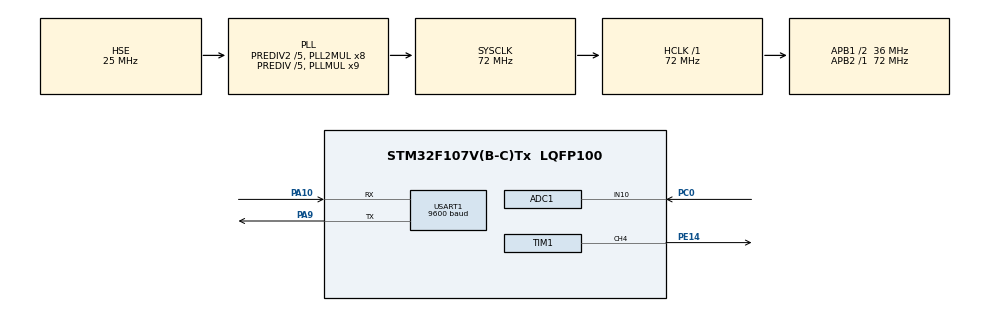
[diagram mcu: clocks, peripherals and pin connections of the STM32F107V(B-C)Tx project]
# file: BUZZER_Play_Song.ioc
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ADC1.Channel-0\#ChannelRegularConversion=ADC_CHANNEL_10
ADC1.NbrOfConversionFlag=1
ADC1.Rank-0\#ChannelRegularConversion=1
ADC1.SamplingTime-0\#ChannelRegularConversion=ADC_SAMPLETIME_1CYCLE_5
ADC1.master=1
Mcu.Family=STM32F1
Mcu.Name=STM32F107V(B-C)Tx
Mcu.Package=LQFP100
NVIC.PriorityGroup=NVIC_PRIORITYGROUP_4
OSC_IN.Mode=HSE-External-Oscillator
OSC_IN.Signal=RCC_OSC_IN
OSC_OUT.Mode=HSE-External-Oscillator
OSC_OUT.Signal=RCC_OSC_OUT
PA10.Mode=Asynchronous
PA10.Signal=USART1_RX
PA13.Mode=Serial_Wire
PA13.Signal=SYS_JTMS-SWDIO
PA14.Mode=Serial_Wire
PA14.Signal=SYS_JTCK-SWCLK
PA9.Mode=Asynchronous
PA9.Signal=USART1_TX
PC0.Signal=ADCx_IN10
PE14.Signal=S_TIM1_CH4
ProjectManager.HeapSize=0x200
ProjectManager.StackSize=0x400
ProjectManager.TargetToolchain=MDK-ARM V5
RCC.ADCPresc=RCC_ADCPCLK2_DIV8
RCC.AHBFreq_Value=72000000
RCC.APB1CLKDivider=RCC_HCLK_DIV2
RCC.APB1Freq_Value=36000000
RCC.APB1TimFreq_Value=72000000
RCC.APB2Freq_Value=72000000
RCC.APB2TimFreq_Value=72000000
RCC.HCLKFreq_Value=72000000
RCC.HSEDivPLL=RCC_HSE_PREDIV_DIV5
RCC.HSE_VALUE=25000000
RCC.PLLMUL=RCC_PLL_MUL9
RCC.PLLSourceVirtual=RCC_PLLSOURCE_HSE
RCC.Prediv1Source=RCC_PREDIV1_SOURCE_PLL2
RCC.Prediv2=RCC_HSE_PREDIV2_DIV5
RCC.SYSCLKFreq_VALUE=72000000
RCC.SYSCLKSource=RCC_SYSCLKSOURCE_PLLCLK
RCC.USBFreq_Value=48000000
SH.ADCx_IN10.0=ADC1_IN10,IN10
SH.S_TIM1_CH4.0=TIM1_CH4,PWM Generation4 CH4
TIM1.Channel-PWM\ Generation4\ CH4=TIM_CHANNEL_4
TIM1.Period=0xFFFF
TIM1.Prescaler=21
TIM1.Pulse-PWM\ Generation4\ CH4=50
USART1.BaudRate=9600
USART1.VirtualMode=VM_ASYNC
board=custom

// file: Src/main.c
/* USER CODE BEGIN Header */
/**
  ******************************************************************************
  * @file           : main.c
  * @brief          : Main program body
  ******************************************************************************
  ** This notice applies to any and all portions of this file
  * that are not between comment pairs USER CODE BEGIN and
  * USER CODE END. Other portions of this file, whether
  * inserted by the user or by software development tools
  * are owned by their respective copyright owners.
  *
  * COPYRIGHT(c) 2019 STMicroelectronics
  *
  * Redistribution and use in source and binary forms, with or without modification,
  * are permitted provided that the following conditions are met:
  *   1. Redistributions of source code must retain the above copyright notice,
  *      this list of conditions and the following disclaimer.
  *   2. Redistributions in binary form must reproduce the above copyright notice,
  *      this list of conditions and the following disclaimer in the documentation
  *      and/or other materials provided with the distribution.
  *   3. Neither the name of STMicroelectronics nor the names of its contributors
  *      may be used to endorse or promote products derived from this software
  *      without specific prior written permission.
  *
  * THIS SOFTWARE IS PROVIDED BY THE COPYRIGHT HOLDERS AND CONTRIBUTORS "AS IS"
  * AND ANY EXPRESS OR IMPLIED WARRANTIES, INCLUDING, BUT NOT LIMITED TO, THE
  * IMPLIED WARRANTIES OF MERCHANTABILITY AND FITNESS FOR A PARTICULAR PURPOSE ARE
  * DISCLAIMED. IN NO EVENT SHALL THE COPYRIGHT HOLDER OR CONTRIBUTORS BE LIABLE
  * FOR ANY DIRECT, INDIRECT, INCIDENTAL, SPECIAL, EXEMPLARY, OR CONSEQUENTIAL
  * DAMAGES (INCLUDING, BUT NOT LIMITED TO, PROCUREMENT OF SUBSTITUTE GOODS OR
  * SERVICES; LOSS OF USE, DATA, OR PROFITS; OR BUSINESS INTERRUPTION) HOWEVER
  * CAUSED AND ON ANY THEORY OF LIABILITY, WHETHER IN CONTRACT, STRICT LIABILITY,
  * OR TORT (INCLUDING NEGLIGENCE OR OTHERWISE) ARISING IN ANY WAY OUT OF THE USE
  * OF THIS SOFTWARE, EVEN IF ADVISED OF THE POSSIBILITY OF SUCH DAMAGE.
  *
  ******************************************************************************
  */
/* USER CODE END Header */

#include "main.h"

/* USER CODE BEGIN Includes */
#include <math.h>
/* USER CODE END Includes */

ADC_HandleTypeDef hadc1;

TIM_HandleTypeDef htim1;

UART_HandleTypeDef huart1;

/* USER CODE BEGIN PV */
int8_t song[] = {-3, 2, 5, 4, 2, 5, 2, 4, 2, -2, 0, -3};
uint8_t songSize = 12;
/* USER CODE END PV */

void SystemClock_Config(void);
static void MX_GPIO_Init(void);
static void MX_TIM1_Init(void);
static void MX_ADC1_Init(void);
static void MX_USART1_UART_Init(void);

	uint8_t data[1] = {'0'};

int main(void)
{

  /* MCU Configuration--------------------------------------------------------*/

  /* Reset of all peripherals, Initializes the Flash interface and the Systick. */
  HAL_Init();

  /* Configure the system clock */
  SystemClock_Config();

  /* Initialize all configured peripherals */
  MX_GPIO_Init();
  MX_TIM1_Init();
  MX_ADC1_Init();
  MX_USART1_UART_Init();
  /* USER CODE BEGIN 2 */
	HAL_TIM_PWM_Start(&htim1,TIM_CHANNEL_4);
	HAL_ADCEx_Calibration_Start(&hadc1);
  /* USER CODE END 2 */

  /* Infinite loop */
  /* USER CODE BEGIN WHILE */
	uint32_t adcReturnValue = 0;
	int8_t n = 0;
	double_t noteFreq = 440;
	uint16_t arr = 1000;
	uint16_t songIndex = 0;

  while (1)
  {

		/*

		LAB PART 1 - 1
			if (songIndex<songSize){
				n = song[songIndex++] - 6;
				noteFreq = 440*pow(1.059463094359, n);
				arr = (double_t)72000000 / noteFreq / (htim1.Init.Prescaler+ 1) - 1;
				__HAL_TIM_SET_AUTORELOAD(&htim1, arr);//set the new period
				__HAL_TIM_SET_COMPARE(&htim1, TIM_CHANNEL_4, (int)arr/2);//keep 50% duty cycle
				__NOP();
			}
			HAL_Delay(500);
		*/

		/*
			LAB PART 1 - 2

		HAL_ADC_Start(&hadc1);

		if ( HAL_ADC_PollForConversion(&hadc1,1000) == HAL_OK){
			adcReturnValue = HAL_ADC_GetValue(&hadc1);
			n = floor(adcReturnValue / 42.217) - 36;
			noteFreq = 440*pow(1.059463094359, n);
			arr = (double_t)72000000 / noteFreq / (htim1.Init.Prescaler+ 1) - 1;
			__HAL_TIM_SET_AUTORELOAD(&htim1, arr);//set the new period
			__HAL_TIM_SET_COMPARE(&htim1, TIM_CHANNEL_4, (int)arr/2);//keep 50% duty cycle
		}
		HAL_Delay(100);
		HAL_ADC_Stop(&hadc1);*/

			/*
						LAB PART 2

				HAL_UART_Receive(&huart1, data, sizeof(data), HAL_MAX_DELAY);

				n = (int8_t)data[0] - 63;
				noteFreq = 440*pow(1.059463094359, n);
				arr = (double_t)72000000 / noteFreq / (htim1.Init.Prescaler+ 1) - 1;
				__HAL_TIM_SET_AUTORELOAD(&htim1, arr);//set the new period
				__HAL_TIM_SET_COMPARE(&htim1, TIM_CHANNEL_4, (int)arr/2);//keep 50% duty cycle
				__NOP();

			HAL_Delay(500);
			 HAL_UART_Transmit(&huart1, data, sizeof(data), HAL_MAX_DELAY);

			*/
    /* USER CODE END WHILE */

  }
}

void SystemClock_Config(void)
{
  RCC_OscInitTypeDef RCC_OscInitStruct = {0};
  RCC_ClkInitTypeDef RCC_ClkInitStruct = {0};
  RCC_PeriphCLKInitTypeDef PeriphClkInit = {0};

  /**Initializes the CPU, AHB and APB busses clocks
  */
  RCC_OscInitStruct.OscillatorType = RCC_OSCILLATORTYPE_HSE;
  RCC_OscInitStruct.HSEState = RCC_HSE_ON;
  RCC_OscInitStruct.HSEPredivValue = RCC_HSE_PREDIV_DIV5;
  RCC_OscInitStruct.HSIState = RCC_HSI_ON;
  RCC_OscInitStruct.Prediv1Source = RCC_PREDIV1_SOURCE_PLL2;
  RCC_OscInitStruct.PLL.PLLState = RCC_PLL_ON;
  RCC_OscInitStruct.PLL.PLLSource = RCC_PLLSOURCE_HSE;
  RCC_OscInitStruct.PLL.PLLMUL = RCC_PLL_MUL9;
  RCC_OscInitStruct.PLL2.PLL2State = RCC_PLL2_ON;
  RCC_OscInitStruct.PLL2.PLL2MUL = RCC_PLL2_MUL8;
  RCC_OscInitStruct.PLL2.HSEPrediv2Value = RCC_HSE_PREDIV2_DIV5;
  if (HAL_RCC_OscConfig(&RCC_OscInitStruct) != HAL_OK)
  {
    Error_Handler();
  }
  /**Initializes the CPU, AHB and APB busses clocks
  */
  RCC_ClkInitStruct.ClockType = RCC_CLOCKTYPE_HCLK|RCC_CLOCKTYPE_SYSCLK
                              |RCC_CLOCKTYPE_PCLK1|RCC_CLOCKTYPE_PCLK2;
  RCC_ClkInitStruct.SYSCLKSource = RCC_SYSCLKSOURCE_PLLCLK;
  RCC_ClkInitStruct.AHBCLKDivider = RCC_SYSCLK_DIV1;
  RCC_ClkInitStruct.APB1CLKDivider = RCC_HCLK_DIV2;
  RCC_ClkInitStruct.APB2CLKDivider = RCC_HCLK_DIV1;

  if (HAL_RCC_ClockConfig(&RCC_ClkInitStruct, FLASH_LATENCY_2) != HAL_OK)
  {
    Error_Handler();
  }
  PeriphClkInit.PeriphClockSelection = RCC_PERIPHCLK_ADC;
  PeriphClkInit.AdcClockSelection = RCC_ADCPCLK2_DIV8;
  if (HAL_RCCEx_PeriphCLKConfig(&PeriphClkInit) != HAL_OK)
  {
    Error_Handler();
  }
  /**Configure the Systick interrupt time
  */
  __HAL_RCC_PLLI2S_ENABLE();
}

static void MX_ADC1_Init(void)
{

  ADC_ChannelConfTypeDef sConfig = {0};

  /**Common config
  */
  hadc1.Instance = ADC1;
  hadc1.Init.ScanConvMode = ADC_SCAN_DISABLE;
  hadc1.Init.ContinuousConvMode = DISABLE;
  hadc1.Init.DiscontinuousConvMode = DISABLE;
  hadc1.Init.ExternalTrigConv = ADC_SOFTWARE_START;
  hadc1.Init.DataAlign = ADC_DATAALIGN_RIGHT;
  hadc1.Init.NbrOfConversion = 1;
  if (HAL_ADC_Init(&hadc1) != HAL_OK)
  {
    Error_Handler();
  }
  /**Configure Regular Channel
  */
  sConfig.Channel = ADC_CHANNEL_10;
  sConfig.Rank = ADC_REGULAR_RANK_1;
  sConfig.SamplingTime = ADC_SAMPLETIME_1CYCLE_5;
  if (HAL_ADC_ConfigChannel(&hadc1, &sConfig) != HAL_OK)
  {
    Error_Handler();
  }

}

static void MX_TIM1_Init(void)
{

  TIM_MasterConfigTypeDef sMasterConfig = {0};
  TIM_OC_InitTypeDef sConfigOC = {0};
  TIM_BreakDeadTimeConfigTypeDef sBreakDeadTimeConfig = {0};

  htim1.Instance = TIM1;
  htim1.Init.Prescaler = 21;
  htim1.Init.CounterMode = TIM_COUNTERMODE_UP;
  htim1.Init.Period = 0xFFFF;
  htim1.Init.ClockDivision = TIM_CLOCKDIVISION_DIV1;
  htim1.Init.RepetitionCounter = 0;
  htim1.Init.AutoReloadPreload = TIM_AUTORELOAD_PRELOAD_DISABLE;
  if (HAL_TIM_PWM_Init(&htim1) != HAL_OK)
  {
    Error_Handler();
  }
  sMasterConfig.MasterOutputTrigger = TIM_TRGO_RESET;
  sMasterConfig.MasterSlaveMode = TIM_MASTERSLAVEMODE_DISABLE;
  if (HAL_TIMEx_MasterConfigSynchronization(&htim1, &sMasterConfig) != HAL_OK)
  {
    Error_Handler();
  }
  sConfigOC.OCMode = TIM_OCMODE_PWM1;
  sConfigOC.Pulse = 50;
  sConfigOC.OCPolarity = TIM_OCPOLARITY_HIGH;
  sConfigOC.OCFastMode = TIM_OCFAST_DISABLE;
  sConfigOC.OCIdleState = TIM_OCIDLESTATE_RESET;
  sConfigOC.OCNIdleState = TIM_OCNIDLESTATE_RESET;
  if (HAL_TIM_PWM_ConfigChannel(&htim1, &sConfigOC, TIM_CHANNEL_4) != HAL_OK)
  {
    Error_Handler();
  }
  sBreakDeadTimeConfig.OffStateRunMode = TIM_OSSR_DISABLE;
  sBreakDeadTimeConfig.OffStateIDLEMode = TIM_OSSI_DISABLE;
  sBreakDeadTimeConfig.LockLevel = TIM_LOCKLEVEL_OFF;
  sBreakDeadTimeConfig.DeadTime = 0;
  sBreakDeadTimeConfig.BreakState = TIM_BREAK_DISABLE;
  sBreakDeadTimeConfig.BreakPolarity = TIM_BREAKPOLARITY_HIGH;
  sBreakDeadTimeConfig.AutomaticOutput = TIM_AUTOMATICOUTPUT_DISABLE;
  if (HAL_TIMEx_ConfigBreakDeadTime(&htim1, &sBreakDeadTimeConfig) != HAL_OK)
  {
    Error_Handler();
  }
  HAL_TIM_MspPostInit(&htim1);

}

static void MX_USART1_UART_Init(void)
{

  huart1.Instance = USART1;
  huart1.Init.BaudRate = 9600;
  huart1.Init.WordLength = UART_WORDLENGTH_8B;
  huart1.Init.StopBits = UART_STOPBITS_1;
  huart1.Init.Parity = UART_PARITY_NONE;
  huart1.Init.Mode = UART_MODE_TX_RX;
  huart1.Init.HwFlowCtl = UART_HWCONTROL_NONE;
  huart1.Init.OverSampling = UART_OVERSAMPLING_16;
  if (HAL_UART_Init(&huart1) != HAL_OK)
  {
    Error_Handler();
  }

}

static void MX_GPIO_Init(void)
{

  /* GPIO Ports Clock Enable */
  __HAL_RCC_GPIOC_CLK_ENABLE();
  __HAL_RCC_GPIOE_CLK_ENABLE();
  __HAL_RCC_GPIOA_CLK_ENABLE();

}

void Error_Handler(void)
{
}

/************************ (C) COPYRIGHT STMicroelectronics *****END OF FILE****/
